AUTOSAR XML (schema 4-2-2)
package /Components
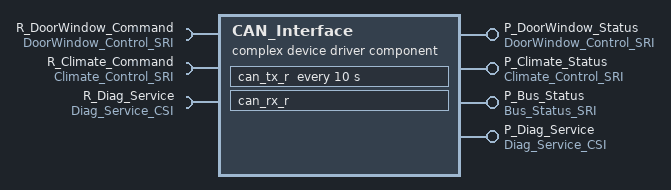
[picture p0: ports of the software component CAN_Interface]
  complex device driver sw component type CAN_Interface
    4 x provide port:
      P_DoorWindow_Status: provided-interface=DoorWindow_Control_SRI
      P_Climate_Status: provided-interface=Climate_Control_SRI
      P_Bus_Status: provided-interface=Bus_Status_SRI
      P_Diag_Service: provided-interface=Diag_Service_CSI
    require port R_DoorWindow_Command: required-interface=DoorWindow_Control_SRI
    require port R_Climate_Command: required-interface=Climate_Control_SRI
    require port R_Diag_Service: required-interface=Diag_Service_CSI
    behavior CAN_Interface_InternalBehavior
      init event CAN_Init: start-on-event=can_rx_r
      operation invoked event CAN_Diag_Call: start-on-event=can_rx_r, operation=P_Diag_Service.ReadDTC
      timing event CAN_Tx_Schedule: start-on-event=can_tx_r, period=10
      runnable can_tx_r: minimum-start-interval=1, symbol=CAN_Interface_can_tx_r
        data-receive-point-by-values:
          5 x access:
            rx_door_lock_cmd_access: accessed-variable=R_DoorWindow_Command.door_lock_cmd
            rx_window_move_cmd_access: accessed-variable=R_DoorWindow_Command.window_move_cmd
            rx_hvac_target_temp_access: accessed-variable=R_Climate_Command.hvac_target_temp
            rx_fan_speed_cmd_access: accessed-variable=R_Climate_Command.fan_speed_cmd
            rx_ac_on_cmd_access: accessed-variable=R_Climate_Command.ac_on_cmd
        data-send-points:
          access tx_bus_online_access: accessed-variable=P_Bus_Status.bus_online
          access tx_bus_error_count_access: accessed-variable=P_Bus_Status.bus_error_count
          access tx_bus_load_access: accessed-variable=P_Bus_Status.bus_load
        sync call scp_get_update_status: operation=R_Diag_Service.GetUpdateStatus, timeout=1000
      runnable can_rx_r: minimum-start-interval=1, symbol=CAN_Interface_can_rx_r
        data-receive-point-by-values:
          access rx_ac_on_cmd_access_rx: accessed-variable=R_Climate_Command.ac_on_cmd
        data-send-points:
          4 x access:
            tx_door_status_access: accessed-variable=P_DoorWindow_Status.door_status
            tx_window_position_access: accessed-variable=P_DoorWindow_Status.window_position
            tx_cabin_temp_feedback_access: accessed-variable=P_Climate_Status.cabin_temp_feedback
            tx_ac_status_access: accessed-variable=P_Climate_Status.ac_status
        sync call scp_read_dtc: operation=R_Diag_Service.ReadDTC, timeout=1000
        sync call scp_clear_dtc: operation=R_Diag_Service.ClearDTC, timeout=1000
